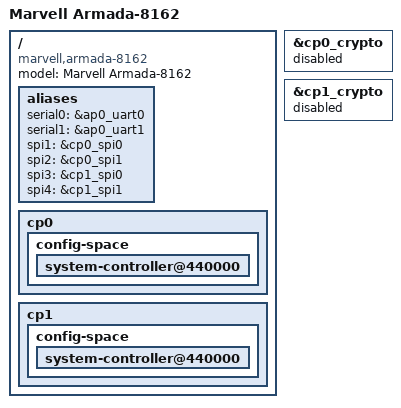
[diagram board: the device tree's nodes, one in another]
// SPDX-License-Identifier: (GPL-2.0+ OR MIT)
/*
 * Copyright (C) 2018 Marvell Technology Group Ltd.
 *
 * Device Tree file for Marvell Armada-8162 SoC, made of two AP810 and
 * two CP110.
 */

#include "armada-common.dtsi"
#include "armada-8kp.dtsi"
#include "armada-ap810-ap0.dtsi"

#define AP_NUM				0
#define AP810_BASE			0xe8000000
#define AP810_GIC_ITS_BASE		0xf040000
#include "armada-ap810-octa-core.dtsi"
/* CP110-0 Settings */
#define CP110_NUM		0

#include "armada-cp110.dtsi"

#undef CP110_NUM

#undef AP_NUM
#undef AP810_BASE
#undef AP810_GIC_ITS_BASE

#define AP_NUM				1
#define AP810_BASE			0xe4000000
#define AP810_GIC_ITS_BASE		0xb040000
#include "armada-ap810-octa-core.dtsi"

/* CP110-1 Settings */
#define CP110_NUM		1

#include "armada-cp110.dtsi"

#undef CP110_NUM

/* AP810 definitions are used in CP110 dtsi files, so un-define them after defining it's connected CPs */
#undef AP_NUM
#undef AP810_BASE
#undef AP810_GIC_ITS_BASE

/ {
	model = "Marvell Armada-8162";
	compatible = "marvell,armada-8162", "marvell,armada-ap810-octa",
				"marvell,armada-ap810";

	aliases {
		serial0 = &ap0_uart0;
		serial1 = &ap0_uart1;
		spi1 = &cp0_spi0;
		spi2 = &cp0_spi1;
		spi3 = &cp1_spi0;
		spi4 = &cp1_spi1;
	};

	/* Delete unsupported interfaces from CP nodes:
	 *	1. GPIO in CP requires a pinctrl driver support,
	 *	   which is currently not suitable for AP810.
	 */
	cp0 {
		config-space {
			system-controller@440000 {
				/delete-node/ gpio@100;
				/delete-node/ gpio@140;
			};
		};
	};
	cp1 {
		config-space {
			system-controller@440000 {
				/delete-node/ gpio@100;
				/delete-node/ gpio@140;
			};
		};
	};
};

&cp0_crypto {
	status = "disabled";
};

&cp1_crypto {
	status = "disabled";
};
